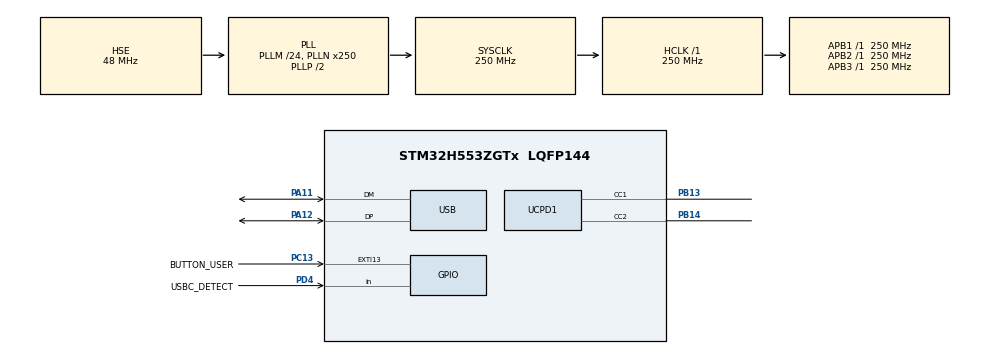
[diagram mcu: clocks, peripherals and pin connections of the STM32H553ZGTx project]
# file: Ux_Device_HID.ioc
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CORTEX_M33_NS.userName=CORTEX_M33
GPDMA1.DIRECTION_GPDMACH0=DMA_MEMORY_TO_PERIPH
GPDMA1.IPHANDLE_GPDMACH0-SIMPLEREQUEST_GPDMACH0=__NULL
GPDMA1.IPHANDLE_GPDMACH1-SIMPLEREQUEST_GPDMACH1=__NULL
GPDMA1.REQUEST_GPDMACH0=GPDMA1_REQUEST_UCPD1_TX
GPDMA1.REQUEST_GPDMACH1=GPDMA1_REQUEST_UCPD1_RX
Mcu.Family=STM32H5
Mcu.Name=STM32H553ZGTx
Mcu.Package=LQFP144
NVIC.EXTI13_IRQn=true\:7\:0\:true\:false\:true\:false\:true\:true\:true
NVIC.GPDMA1_Channel0_IRQn=true\:0\:0\:false\:false\:true\:true\:false\:true\:true
NVIC.GPDMA1_Channel1_IRQn=true\:0\:0\:false\:false\:true\:true\:false\:true\:true
NVIC.PriorityGroup=NVIC_PRIORITYGROUP_4
NVIC.TIM6_IRQn=true\:15\:0\:false\:false\:true\:false\:false\:true\:true
NVIC.TimeBase=TIM6_IRQn
NVIC.TimeBaseIP=TIM6
NVIC.UCPD1_IRQn=true\:5\:0\:true\:false\:true\:false\:true\:false\:true
NVIC.USB_DRD_FS_IRQn=true\:6\:0\:true\:false\:true\:false\:true\:true\:true
PA11.Mode=Device
PA11.Signal=USB_DM
PA12.Mode=Device
PA12.Signal=USB_DP
PB13.Mode=Sink_AllSignals
PB13.Signal=UCPD1_CC1
PB14.Mode=Sink_AllSignals
PB14.Signal=UCPD1_CC2
PC13.GPIO_Label=BUTTON_USER
PC13.GPIO_ModeDefaultEXTI=GPIO_MODE_IT_FALLING
PC13.GPIO_PuPd=GPIO_PULLDOWN
PC13.Signal=GPXTI13
PD4.GPIO_Label=USBC_DETECT
PD4.Signal=GPIO_Input
PH0-OSC_IN(PH0).Mode=HSE-External-Oscillator
PH0-OSC_IN(PH0).Signal=RCC_OSC_IN
PH1-OSC_OUT(PH1).Mode=HSE-External-Oscillator
PH1-OSC_OUT(PH1).Signal=RCC_OSC_OUT
ProjectManager.HeapSize=0x400
ProjectManager.StackSize=0x800
ProjectManager.TargetToolchain=EWARM V9.20
RCC.ADCFreq_Value=250000000
RCC.AHBFreq_Value=250000000
RCC.APB1Freq_Value=250000000
RCC.APB1TimFreq_Value=250000000
RCC.APB2Freq_Value=250000000
RCC.APB2TimFreq_Value=250000000
RCC.APB3Freq_Value=250000000
RCC.CSI_VALUE=4000000
RCC.CortexFreq_Value=250000000
RCC.EPOD_VALUE=48000000
RCC.HCLKFreq_Value=250000000
RCC.HSE_VALUE=48000000
RCC.HSI48_VALUE=48000000
RCC.HSI_VALUE=64000000
RCC.LSE_VALUE=32768
RCC.LSIRC_VALUE=32000
RCC.PLL2FRACN=0
RCC.PLLFRACN=0
RCC.PLLM=24
RCC.PLLN=250
RCC.PLLSourceVirtual=RCC_PLL1_SOURCE_HSE
RCC.SYSCLKFreq_VALUE=250000000
RCC.SYSCLKSource=RCC_SYSCLKSOURCE_PLLCLK
RCC.USBFreq_Value=48000000
RCC.VCOOutputFreq_Value=500000000
USB.VirtualMode=Device_Only
USBX.BSP.number=1
USBX.Core_System=1
USBX.MAX_POWER_IN_MILLI_AMPER=0
USBX.USBD_COMPOSITE_USE_IAD=0
USBX.USBD_PRODUCT_STRING=STM32 HID Mouse Device
USBX.USBD_SERIAL_NUMBER=HID001
USBX.USBX_SYS_SIZE=1024 * 4
USBX.UX_APP_MEM_POOL_SIZE=1024 * 7
USBX.UX_DEVICE_ENABLED_FS=1
USBX.UX_DEVICE_HID_CORE=1
USBX.UX_DEVICE_HID_MOUSE=1
USBX.UX_Device_Controller=1
USBX.UX_Device_CoreStack=1
USBX.UX_SLAVE_REQUEST_DATA_MAX_LENGTH=64
USBX.UX_enabled_FS=1
USBX0.BSP.STBoard=false
USBX0.BSP.api=Unknown
USBX0.BSP.condition=\!DIE47A
USBX0.BSP.instance=USB
USBX0.BSP.ip=USB
USBX0.BSP.mode=Device_Only
USBX0.BSP.name=USB_Device
USBX0.BSP.solution=USB
VP_CORTEX_M33_NS_VS_Hclk.Mode=Hclk_Mode
VP_GPDMA1_VS_GPDMACH0.Mode=SIMPLEREQUEST_GPDMACH0
VP_GPDMA1_VS_GPDMACH1.Mode=SIMPLEREQUEST_GPDMACH1
VP_ICACHE_VS_ICACHE.Mode=DefaultMode
VP_PWR_VS_LPOM.Mode=PowerOptimisation
VP_PWR_VS_SECSignals.Mode=Security/Privilege
VP_SYS_VS_tim6.Mode=TIM6
VP_THREADX_VS_RTOSJjThreadXJjCoreJjDefault.Mode=Core_Default
VP_USBPD_VS_PD3TYPEC.Mode=PD3_TypeC
VP_USBPD_VS_USBPD1.Mode=USBPD_P0
VP_USBPD_VS_usbpd_tim2.Mode=TIM2
VP_USBPD_VS_usbpd_usb_cohabitation.Mode=Enable USB Support
VP_USBX_Core_System.Mode=Core_System
VP_USBX_UX\ Device\ Controller_FS.Mode=UX_Device_Controller_FS
VP_USBX_UX\ Device\ CoreStack_FS.Mode=UX_Device_CoreStack
VP_USBX_UX\ Device\ HID_CORE_FS.Mode=UX_Device_class_HID_CORE_FS_HS
VP_USBX_UX\ Device\ HID_MOUSE_FS.Mode=UX_Device_class_HID_MOUSE_FS_HS
board=custom

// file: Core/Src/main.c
/* USER CODE BEGIN Header */
/**
  ******************************************************************************
  * @file           : main.c
  * @brief          : Main program body
  ******************************************************************************
  * @attention
  *
  * Copyright (c) 2026 STMicroelectronics.
  * All rights reserved.
  *
  * This software is licensed under terms that can be found in the LICENSE file
  * in the root directory of this software component.
  * If no LICENSE file comes with this software, it is provided AS-IS.
  *
  ******************************************************************************
  */
/* USER CODE END Header */
#include "app_threadx.h"
#include "main.h"
#include "usbpd.h"

PCD_HandleTypeDef hpcd_USB_DRD_FS;

void SystemClock_Config(void);
static void MX_GPIO_Init(void);
static void MX_GPDMA1_Init(void);
static void MX_ICACHE_Init(void);
static void MX_UCPD1_Init(void);

int main(void)
{

  /* MCU Configuration--------------------------------------------------------*/

  /* Reset of all peripherals, Initializes the Flash interface and the Systick. */
  HAL_Init();

  /* Configure the system clock */
  SystemClock_Config();

  /* Initialize all configured peripherals */
  MX_GPIO_Init();
  MX_GPDMA1_Init();
  MX_ICACHE_Init();
  MX_UCPD1_Init();
  /* Call PreOsInit function */
  USBPD_PreInitOs();

  MX_ThreadX_Init();

  /* We should never get here as control is now taken by the scheduler */

  /* Infinite loop */
  while (1)
  {

  }
}

void SystemClock_Config(void)
{
  RCC_OscInitTypeDef RCC_OscInitStruct = {0};
  RCC_ClkInitTypeDef RCC_ClkInitStruct = {0};

  /** Configure the main internal regulator output voltage
  */
  __HAL_PWR_VOLTAGESCALING_CONFIG(PWR_REGULATOR_VOLTAGE_SCALE0);

  while(!__HAL_PWR_GET_FLAG(PWR_FLAG_VOSRDY)) {}

  /** Initializes the RCC Oscillators according to the specified parameters
  * in the RCC_OscInitTypeDef structure.
  */
  RCC_OscInitStruct.OscillatorType = RCC_OSCILLATORTYPE_HSI48|RCC_OSCILLATORTYPE_HSI
                              |RCC_OSCILLATORTYPE_HSE;
  RCC_OscInitStruct.HSEState = RCC_HSE_ON;
  RCC_OscInitStruct.HSIState = RCC_HSI_ON;
  RCC_OscInitStruct.HSIDiv = RCC_HSI_DIV2;
  RCC_OscInitStruct.HSICalibrationValue = RCC_HSICALIBRATION_DEFAULT;
  RCC_OscInitStruct.HSI48State = RCC_HSI48_ON;
  RCC_OscInitStruct.PLL.PLLState = RCC_PLL_ON;
  RCC_OscInitStruct.PLL.PLLSource = RCC_PLL1_SOURCE_HSE;
  RCC_OscInitStruct.PLL.PLLM = 24;
  RCC_OscInitStruct.PLL.PLLN = 250;
  RCC_OscInitStruct.PLL.PLLP = 2;
  RCC_OscInitStruct.PLL.PLLQ = 2;
  RCC_OscInitStruct.PLL.PLLR = 2;
  RCC_OscInitStruct.PLL.PLLRGE = RCC_PLL1_VCIRANGE_1;
  RCC_OscInitStruct.PLL.PLLVCOSEL = RCC_PLL1_VCORANGE_WIDE;
  RCC_OscInitStruct.PLL.PLLFRACN = 0;
  if (HAL_RCC_OscConfig(&RCC_OscInitStruct) != HAL_OK)
  {
    Error_Handler();
  }

  /** Initializes the CPU, AHB and APB buses clocks
  */
  RCC_ClkInitStruct.ClockType = RCC_CLOCKTYPE_HCLK|RCC_CLOCKTYPE_SYSCLK
                              |RCC_CLOCKTYPE_PCLK1|RCC_CLOCKTYPE_PCLK2
                              |RCC_CLOCKTYPE_PCLK3;
  RCC_ClkInitStruct.SYSCLKSource = RCC_SYSCLKSOURCE_PLLCLK;
  RCC_ClkInitStruct.AHBCLKDivider = RCC_SYSCLK_DIV1;
  RCC_ClkInitStruct.APB1CLKDivider = RCC_HCLK_DIV1;
  RCC_ClkInitStruct.APB2CLKDivider = RCC_HCLK_DIV1;
  RCC_ClkInitStruct.APB3CLKDivider = RCC_HCLK_DIV1;

  if (HAL_RCC_ClockConfig(&RCC_ClkInitStruct, FLASH_LATENCY_5) != HAL_OK)
  {
    Error_Handler();
  }

  /** Configure the programming delay
  */
  __HAL_FLASH_SET_PROGRAM_DELAY(FLASH_PROGRAMMING_DELAY_2);
}

static void MX_GPDMA1_Init(void)
{

  /* Peripheral clock enable */
  __HAL_RCC_GPDMA1_CLK_ENABLE();

  /* GPDMA1 interrupt Init */
    HAL_NVIC_SetPriority(GPDMA1_Channel0_IRQn, 0, 0);
    HAL_NVIC_EnableIRQ(GPDMA1_Channel0_IRQn);
    HAL_NVIC_SetPriority(GPDMA1_Channel1_IRQn, 0, 0);
    HAL_NVIC_EnableIRQ(GPDMA1_Channel1_IRQn);

}

static void MX_ICACHE_Init(void)
{

  /** Enable instruction cache (default 2-ways set associative cache)
  */
  if (HAL_ICACHE_Enable() != HAL_OK)
  {
    Error_Handler();
  }

}

static void MX_UCPD1_Init(void)
{

  LL_GPIO_InitTypeDef GPIO_InitStruct = {0};
  LL_DMA_InitTypeDef DMA_InitStruct = {0};

  /* Peripheral clock enable */
  LL_APB1_GRP2_EnableClock(LL_APB1_GRP2_PERIPH_UCPD1);

  LL_AHB2_GRP1_EnableClock(LL_AHB2_GRP1_PERIPH_GPIOB);
  /**UCPD1 GPIO Configuration
  PB13   ------> UCPD1_CC1
  PB14   ------> UCPD1_CC2
  */
  GPIO_InitStruct.Pin = LL_GPIO_PIN_13|LL_GPIO_PIN_14;
  GPIO_InitStruct.Mode = LL_GPIO_MODE_ANALOG;
  GPIO_InitStruct.Pull = LL_GPIO_PULL_NO;
  LL_GPIO_Init(GPIOB, &GPIO_InitStruct);

  /* UCPD1 DMA Init */

  /* GPDMA1_REQUEST_UCPD1_RX Init */
  DMA_InitStruct.SrcAddress = 0x00000000U;
  DMA_InitStruct.DestAddress = 0x00000000U;
  DMA_InitStruct.Direction = LL_DMA_DIRECTION_PERIPH_TO_MEMORY;
  DMA_InitStruct.BlkHWRequest = LL_DMA_HWREQUEST_SINGLEBURST;
  DMA_InitStruct.DataAlignment = LL_DMA_DATA_ALIGN_ZEROPADD;
  DMA_InitStruct.SrcBurstLength = 1;
  DMA_InitStruct.DestBurstLength = 1;
  DMA_InitStruct.SrcDataWidth = LL_DMA_SRC_DATAWIDTH_BYTE;
  DMA_InitStruct.DestDataWidth = LL_DMA_DEST_DATAWIDTH_BYTE;
  DMA_InitStruct.SrcIncMode = LL_DMA_SRC_FIXED;
  DMA_InitStruct.DestIncMode = LL_DMA_DEST_FIXED;
  DMA_InitStruct.Priority = LL_DMA_LOW_PRIORITY_LOW_WEIGHT;
  DMA_InitStruct.BlkDataLength = 0x00000000U;
  DMA_InitStruct.TriggerMode = LL_DMA_TRIGM_BLK_TRANSFER;
  DMA_InitStruct.TriggerPolarity = LL_DMA_TRIG_POLARITY_MASKED;
  DMA_InitStruct.TriggerSelection = 0x00000000U;
  DMA_InitStruct.Request = LL_GPDMA1_REQUEST_UCPD1_RX;
  DMA_InitStruct.TransferEventMode = LL_DMA_TCEM_BLK_TRANSFER;
  DMA_InitStruct.Mode = LL_DMA_NORMAL;
  DMA_InitStruct.SrcAllocatedPort = LL_DMA_SRC_ALLOCATED_PORT0;
  DMA_InitStruct.DestAllocatedPort = LL_DMA_DEST_ALLOCATED_PORT0;
  DMA_InitStruct.LinkAllocatedPort = LL_DMA_LINK_ALLOCATED_PORT1;
  DMA_InitStruct.LinkStepMode = LL_DMA_LSM_FULL_EXECUTION;
  DMA_InitStruct.LinkedListBaseAddr = 0x00000000U;
  DMA_InitStruct.LinkedListAddrOffset = 0x00000000U;
  LL_DMA_Init(GPDMA1, LL_DMA_CHANNEL_1, &DMA_InitStruct);

  /* GPDMA1_REQUEST_UCPD1_TX Init */
  DMA_InitStruct.SrcAddress = 0x00000000U;
  DMA_InitStruct.DestAddress = 0x00000000U;
  DMA_InitStruct.Direction = LL_DMA_DIRECTION_MEMORY_TO_PERIPH;
  DMA_InitStruct.BlkHWRequest = LL_DMA_HWREQUEST_SINGLEBURST;
  DMA_InitStruct.DataAlignment = LL_DMA_DATA_ALIGN_ZEROPADD;
  DMA_InitStruct.SrcBurstLength = 1;
  DMA_InitStruct.DestBurstLength = 1;
  DMA_InitStruct.SrcDataWidth = LL_DMA_SRC_DATAWIDTH_BYTE;
  DMA_InitStruct.DestDataWidth = LL_DMA_DEST_DATAWIDTH_BYTE;
  DMA_InitStruct.SrcIncMode = LL_DMA_SRC_FIXED;
  DMA_InitStruct.DestIncMode = LL_DMA_DEST_FIXED;
  DMA_InitStruct.Priority = LL_DMA_LOW_PRIORITY_LOW_WEIGHT;
  DMA_InitStruct.BlkDataLength = 0x00000000U;
  DMA_InitStruct.TriggerMode = LL_DMA_TRIGM_BLK_TRANSFER;
  DMA_InitStruct.TriggerPolarity = LL_DMA_TRIG_POLARITY_MASKED;
  DMA_InitStruct.TriggerSelection = 0x00000000U;
  DMA_InitStruct.Request = LL_GPDMA1_REQUEST_UCPD1_TX;
  DMA_InitStruct.TransferEventMode = LL_DMA_TCEM_BLK_TRANSFER;
  DMA_InitStruct.Mode = LL_DMA_NORMAL;
  DMA_InitStruct.SrcAllocatedPort = LL_DMA_SRC_ALLOCATED_PORT0;
  DMA_InitStruct.DestAllocatedPort = LL_DMA_DEST_ALLOCATED_PORT0;
  DMA_InitStruct.LinkAllocatedPort = LL_DMA_LINK_ALLOCATED_PORT1;
  DMA_InitStruct.LinkStepMode = LL_DMA_LSM_FULL_EXECUTION;
  DMA_InitStruct.LinkedListBaseAddr = 0x00000000U;
  DMA_InitStruct.LinkedListAddrOffset = 0x00000000U;
  LL_DMA_Init(GPDMA1, LL_DMA_CHANNEL_0, &DMA_InitStruct);

  /* UCPD1 interrupt Init */
  NVIC_SetPriority(UCPD1_IRQn, NVIC_EncodePriority(NVIC_GetPriorityGrouping(),5, 0));
  NVIC_EnableIRQ(UCPD1_IRQn);

}

void MX_USB_PCD_Init(void)
{

  hpcd_USB_DRD_FS.Instance = USB_DRD_FS;
  hpcd_USB_DRD_FS.Init.dev_endpoints = 8;
  hpcd_USB_DRD_FS.Init.speed = USBD_FS_SPEED;
  hpcd_USB_DRD_FS.Init.phy_itface = PCD_PHY_EMBEDDED;
  hpcd_USB_DRD_FS.Init.Sof_enable = DISABLE;
  hpcd_USB_DRD_FS.Init.low_power_enable = DISABLE;
  hpcd_USB_DRD_FS.Init.lpm_enable = DISABLE;
  hpcd_USB_DRD_FS.Init.battery_charging_enable = DISABLE;
  hpcd_USB_DRD_FS.Init.vbus_sensing_enable = DISABLE;
  hpcd_USB_DRD_FS.Init.bulk_doublebuffer_enable = DISABLE;
  hpcd_USB_DRD_FS.Init.iso_singlebuffer_enable = DISABLE;
  if (HAL_PCD_Init(&hpcd_USB_DRD_FS) != HAL_OK)
  {
    Error_Handler();
  }
  /* USER CODE BEGIN USB_Init 2 */
  HAL_PCDEx_PMAConfig(&hpcd_USB_DRD_FS, 0x00, PCD_SNG_BUF, 0x0C);
  HAL_PCDEx_PMAConfig(&hpcd_USB_DRD_FS, 0x80, PCD_SNG_BUF, 0x4C);
  HAL_PCDEx_PMAConfig(&hpcd_USB_DRD_FS, 0x81, PCD_SNG_BUF, 0x8C);
  /* USER CODE END USB_Init 2 */

}

static void MX_GPIO_Init(void)
{
  GPIO_InitTypeDef GPIO_InitStruct = {0};

  /* GPIO Ports Clock Enable */
  __HAL_RCC_GPIOC_CLK_ENABLE();
  __HAL_RCC_GPIOH_CLK_ENABLE();
  __HAL_RCC_GPIOB_CLK_ENABLE();
  __HAL_RCC_GPIOA_CLK_ENABLE();
  __HAL_RCC_GPIOD_CLK_ENABLE();

  /*Configure GPIO pin : BUTTON_USER_Pin */
  GPIO_InitStruct.Pin = BUTTON_USER_Pin;
  GPIO_InitStruct.Mode = GPIO_MODE_IT_FALLING;
  GPIO_InitStruct.Pull = GPIO_PULLDOWN;
  HAL_GPIO_Init(BUTTON_USER_GPIO_Port, &GPIO_InitStruct);

  /*Configure GPIO pin : USBC_DETECT_Pin */
  GPIO_InitStruct.Pin = USBC_DETECT_Pin;
  GPIO_InitStruct.Mode = GPIO_MODE_INPUT;
  GPIO_InitStruct.Pull = GPIO_NOPULL;
  HAL_GPIO_Init(USBC_DETECT_GPIO_Port, &GPIO_InitStruct);

  /* EXTI interrupt init*/
  HAL_NVIC_SetPriority(EXTI13_IRQn, 7, 0);
  HAL_NVIC_EnableIRQ(EXTI13_IRQn);

}

void HAL_TIM_PeriodElapsedCallback(TIM_HandleTypeDef *htim)
{
  if (htim->Instance == TIM6)
  {
    HAL_IncTick();
  }
}

void Error_Handler(void)
{
  while (1)
  {
  }
}
